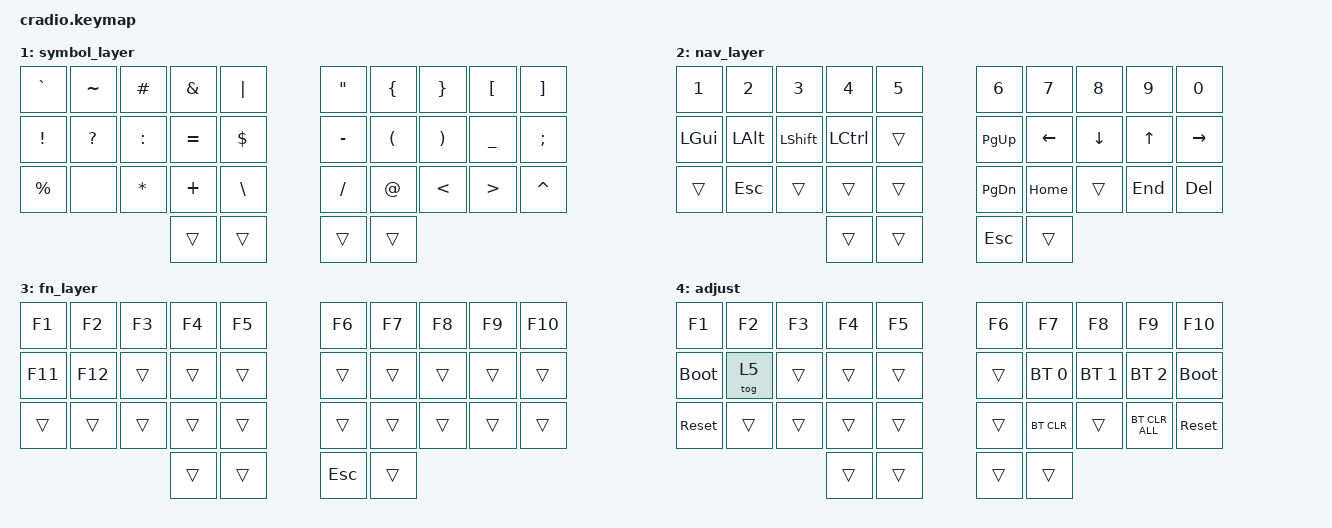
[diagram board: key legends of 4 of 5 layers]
#include <behaviors.dtsi>
#include <dt-bindings/zmk/keys.h>
#include <dt-bindings/zmk/bt.h>

#define TAPPING_TERM 210
#define QUICK_TAP    150
#define IDLE_TERM    110

// Home row mods macros
#define HRML(k1,k2,k3,k4) &ht LGUI k1 &ht LALT k2 &ht LSHFT k3 &ht LCTRL k4
#define HRMR(k1,k2,k3,k4) &ht RCTRL k1 &ht RSHFT k2 &ht LALT k3 &ht RGUI k4

/ {
    behaviors {
        ht: hold_tap {
            compatible = "zmk,behavior-hold-tap";
            #binding-cells = <2>;
            flavor = "balanced";
            tapping-term-ms = <TAPPING_TERM>;
            quick-tap-ms = <QUICK_TAP>;
            require-prior-idle-ms = <IDLE_TERM>;
            bindings = <&kp>, <&kp>;
        };
    };

    conditional_layers {
        compatible = "zmk,conditional-layers";
        tri_layer {
            if-layers = <1 2>;
            then-layer = <4>;
        };
    };

    // Coding digraphs, emitted by the base-layer combos below so the operators
    // that dominate Rust/C/TS/Nix/shell don't cost a symbol-layer hold + two
    // presses each.
    macros {
        cd_arrow: cd_arrow {          // ->
            compatible = "zmk,behavior-macro";
            #binding-cells = <0>;
            bindings = <&kp MINUS &kp GT>;
        };
        cd_fatarrow: cd_fatarrow {    // =>
            compatible = "zmk,behavior-macro";
            #binding-cells = <0>;
            bindings = <&kp EQUAL &kp GT>;
        };
        cd_dcolon: cd_dcolon {        // ::
            compatible = "zmk,behavior-macro";
            #binding-cells = <0>;
            bindings = <&kp COLON &kp COLON>;
        };
        cd_eq: cd_eq {                // ==
            compatible = "zmk,behavior-macro";
            #binding-cells = <0>;
            bindings = <&kp EQUAL &kp EQUAL>;
        };
        cd_neq: cd_neq {              // !=
            compatible = "zmk,behavior-macro";
            #binding-cells = <0>;
            bindings = <&kp EXCL &kp EQUAL>;
        };
        cd_and: cd_and {              // &&
            compatible = "zmk,behavior-macro";
            #binding-cells = <0>;
            bindings = <&kp AMPS &kp AMPS>;
        };
        cd_or: cd_or {                // ||
            compatible = "zmk,behavior-macro";
            #binding-cells = <0>;
            bindings = <&kp PIPE &kp PIPE>;
        };
    };

    // Adjacent non-bigram pairs OFF the home row (which is all mod-taps), so a
    // combo never collides with a home-row mod or a normal typing roll. Tight
    // 50ms window keeps them to deliberate simultaneous presses; base layer only.
    combos {
        compatible = "zmk,combos";
        combo_arrow    { timeout-ms = <50>; key-positions = <2 3>;   bindings = <&cd_arrow>;    layers = <0>; };  // D+W  -> ->
        combo_fatarrow { timeout-ms = <50>; key-positions = <3 4>;   bindings = <&cd_fatarrow>; layers = <0>; };  // W+Z  -> =>
        combo_dcolon   { timeout-ms = <50>; key-positions = <22 23>; bindings = <&cd_dcolon>;   layers = <0>; };  // M+C  -> ::
        combo_eq       { timeout-ms = <50>; key-positions = <23 24>; bindings = <&cd_eq>;       layers = <0>; };  // C+V  -> ==
        combo_neq      { timeout-ms = <50>; key-positions = <25 26>; bindings = <&cd_neq>;      layers = <0>; };  // K+P  -> !=
        combo_or       { timeout-ms = <50>; key-positions = <26 27>; bindings = <&cd_or>;       layers = <0>; };  // P+,  -> ||
        combo_and      { timeout-ms = <50>; key-positions = <5 6>;   bindings = <&cd_and>;      layers = <0>; };  // '+F  -> &&
    };

    keymap {
        compatible = "zmk,keymap";

        /* LAYER 0: GRAPHITE */
        default_layer {
            bindings = <
// ╭──────────┬──────────┬──────────┬──────────┬──────────╮    ╭──────────┬──────────┬──────────┬──────────┬──────────╮
// │    B     │    L     │    D     │    W     │    Z     │    │    '     │    F     │    O     │    U     │    J     │
    &kp B      &kp L      &kp D      &kp W      &kp Z           &kp SQT    &kp F      &kp O      &kp U      &kp J
// ├──────────┼──────────┼──────────┼──────────┼──────────┤    ├──────────┼──────────┼──────────┼──────────┼──────────┤
// │    N     │    R     │    T     │    S     │    G     │    │    Y     │    H     │    A     │    E     │    I     │
    HRML(N,        R,         T,         S)     &kp G           &kp Y      HRMR(H,        A,         E,         I)
// ├──────────┼──────────┼──────────┼──────────┼──────────┤    ├──────────┼──────────┼──────────┼──────────┼──────────┤
// │    Q     │    X     │    M     │    C     │    V     │    │    K     │    P     │    ,     │    .     │   BSPC   │
    &kp Q      &kp X      &kp M      &kp C      &kp V           &kp K      &kp P      &kp COMMA  &kp DOT    &kp BSPC
// ╰──────────┴──────────┴──────────┼──────────┼──────────┤    ├──────────┼──────────┼──────────┴──────────┴──────────╯
                                   &lt 3 TAB   &sk LSHFT       &lt 1 SPACE &lt 2 ENTER
            >;
        };

        /* LAYER 1: SYMBOLS */
        symbol_layer {
            bindings = <
// ╭──────────┬──────────┬──────────┬──────────┬──────────╮    ╭──────────┬──────────┬──────────┬──────────┬──────────╮
// │    `     │    ~     │    #     │    &     │    |     │    │    "     │    {     │    }     │    [     │    ]     │
    &kp GRAVE  &kp TILDE  &kp HASH   &kp AMPS   &kp PIPE        &kp DQT    &kp LBRC   &kp RBRC   &kp LBKT   &kp RBKT
// ├──────────┼──────────┼──────────┼──────────┼──────────┤    ├──────────┼──────────┼──────────┼──────────┼──────────┤
// │    !     │    ?     │    :     │    =     │    $     │    │    -     │    (     │    )     │    _     │    ;     │
    &kp EXCL   &kp QMARK  &kp COLON  &kp EQUAL  &kp DLLR        &kp MINUS  &kp LPAR   &kp RPAR   &kp UNDER  &kp SEMI
// ├──────────┼──────────┼──────────┼──────────┼──────────┤    ├──────────┼──────────┼──────────┼──────────┼──────────┤
// │    %     │          │    *     │    +     │    \     │    │    /     │    @     │    <     │    >     │    ^     │
    &kp PRCNT  &none      &kp STAR   &kp PLUS   &kp BSLH        &kp SLASH  &kp AT     &kp LT     &kp GT     &kp CARET
// ╰──────────┴──────────┴──────────┼──────────┼──────────┤    ├──────────┼──────────┼──────────┴──────────┴──────────╯
                                   &trans     &trans          &trans     &trans
            >;
        };

        /* LAYER 2: NUMBERS & NAVIGATION */
        nav_layer {
            bindings = <
// ╭──────────┬──────────┬──────────┬──────────┬──────────╮    ╭──────────┬──────────┬──────────┬──────────┬──────────╮
// │    1     │    2     │    3     │    4     │    5     │    │    6     │    7     │    8     │    9     │    0     │
    &kp N1     &kp N2     &kp N3     &kp N4     &kp N5          &kp N6     &kp N7     &kp N8     &kp N9     &kp N0
// ├──────────┼──────────┼──────────┼──────────┼──────────┤    ├──────────┼──────────┼──────────┼──────────┼──────────┤
// │   GUI    │   ALT    │   SHFT   │   CTRL   │          │    │   PGUP   │   LEFT   │   DOWN   │    UP    │  RIGHT   │
    &kp LGUI   &kp LALT   &kp LSHFT  &kp LCTRL  &trans          &kp PG_UP  &kp LEFT   &kp DOWN   &kp UP     &kp RIGHT
// ├──────────┼──────────┼──────────┼──────────┼──────────┤    ├──────────┼──────────┼──────────┼──────────┼──────────┤
// │          │          │          │          │          │    │   PGDN   │   HOME   │          │   END    │   DEL    │
    &trans     &kp ESC    &trans     &trans     &trans          &kp PG_DN  &kp HOME   &trans     &kp END    &kp DEL
// ╰──────────┴──────────┴──────────┼──────────┼──────────┤    ├──────────┼──────────┼──────────┴──────────┴──────────╯
                                   &trans     &trans          &kp ESC     &trans
            >;
        };

        /* LAYER 3: FUNCTION KEYS */
        fn_layer {
            bindings = <
// ╭──────────┬──────────┬──────────┬──────────┬──────────╮    ╭──────────┬──────────┬──────────┬──────────┬──────────╮
// │    F1    │    F2    │    F3    │    F4    │    F5    │    │    F6    │    F7    │    F8    │    F9    │   F10    │
    &kp F1     &kp F2     &kp F3     &kp F4     &kp F5          &kp F6     &kp F7     &kp F8     &kp F9     &kp F10
// ├──────────┼──────────┼──────────┼──────────┼──────────┤    ├──────────┼──────────┼──────────┼──────────┼──────────┤
// │   F11    │   F12    │          │          │          │    │          │          │          │          │          │
    &kp F11    &kp F12    &trans     &trans     &trans          &trans     &trans     &trans     &trans     &trans
// ├──────────┼──────────┼──────────┼──────────┼──────────┤    ├──────────┼──────────┼──────────┼──────────┼──────────┤
// │          │          │          │          │          │    │          │          │          │          │          │
    &trans     &trans     &trans     &trans     &trans          &trans     &trans     &trans     &trans     &trans
// ╰──────────┴──────────┴──────────┼──────────┼──────────┤    ├──────────┼──────────┼──────────┴──────────┴──────────╯
                                   &trans     &trans          &kp ESC     &trans
            >;
        };

        /* LAYER 4: ADJUST (BT & SYSTEM) */
        adjust {
            bindings = <
    //╭──────────┬──────────┬──────────┬──────────┬──────────╮   ╭──────────┬──────────┬──────────┬──────────┬──────────╮
    //│  F1      │  F2      │  F3      │  F4      │  F5      │   │  F6      │  F7      │  F8      │  F9      │  F10     │
        &kp F1     &kp F2     &kp F3     &kp F4     &kp F5         &kp F6     &kp F7     &kp F8     &kp F9     &kp F10
    //├──────────┼──────────┼──────────┼──────────┼──────────┤   ├──────────┼──────────┼──────────┼──────────┼──────────┤
    //│BOOTLOADER│          │          │          │          │   │          │PROFILE 0 │PROFILE 1 │PROFILE 2 │BOOTLOADER│
      &bootloader   &tog 5     &trans     &trans     &trans        &trans &bt BT_SEL 0 &bt BT_SEL 1 &bt BT_SEL 2 &bootloader
    //├──────────┼──────────┼──────────┼──────────┼──────────┤   ├──────────┼──────────┼──────────┼──────────┼──────────┤
    //│ RESET    │          │          │          │          │   │          │  CLEAR   │          │CLEAR ALL │  RESET   │
       &sys_reset   &trans     &trans     &trans     &trans         &trans   &bt BT_CLR   &trans &bt BT_CLR_ALL &sys_reset
    //╰──────────┴──────────┴──────────┼──────────┼──────────┤   ├──────────┼──────────┼──────────┴──────────┴──────────╯
                                          &trans     &trans         &trans     &trans
    //                                 ╰──────────┴──────────╯   ╰──────────┴──────────╯
            >;
        };
    };
};
